# PIC32CM2532LS60048 register map
Vendor: Microchip Technology; Series: PIC32CMLS60; File version: 0
CPU: CM23 r0p0, selectable endian, MPU, no FPU, 2 interrupt priority bits
Registers are 32-bit, read-write, reset 0x0 unless marked. A register's access mark holds for its fields unless they carry their own. Offsets are from the block's base; [hi:lo] are bit positions; {n}, {i} and the like mark numbered series; 'fields as' and 'values as' point back to an identical list.

## MPU — Memory Protection Unit
Base 0xE000ED90; register names take the prefix MPU_
Same registers: MPU_NS 0xE002ED90
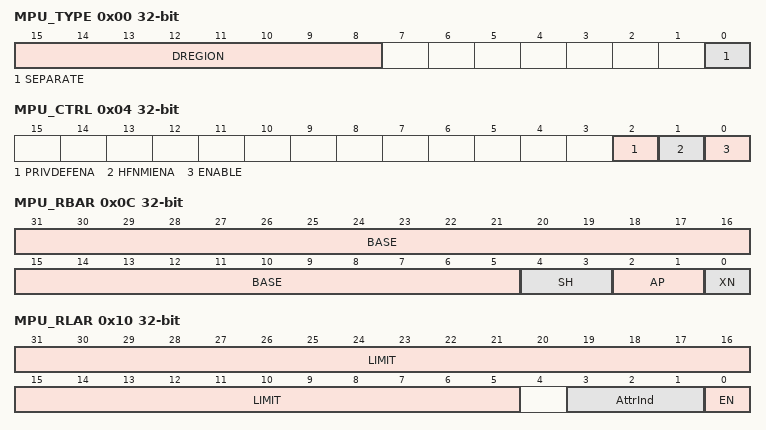
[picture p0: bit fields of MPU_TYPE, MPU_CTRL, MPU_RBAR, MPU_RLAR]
0x00 MPU_TYPE ro
  [15:8] DREGION — Number of MPU data regions
  [0] SEPARATE — Separate instructions and data address regions
0x04 MPU_CTRL — MPU Control Register
  [2] PRIVDEFENA — Privileged default enable
  [1] HFNMIENA — HardFault, NMI enable
  [0] ENABLE — MPU enable
0x08 MPU_RNR — MPU Region Number Register
  [7:0] REGION — Selected region number
0x0C MPU_RBAR — MPU Region Base Address Register
  [31:5] BASE — Base address
  [4:3] SH — Shareability
    0=NO (Non-shareable); 2=OUTER (Outer shareable); 3=INNER (Inner shareable)
  [2:1] AP — Access permissions
    0=RWPRIV (Read/write by privileged code only); 1=RWANY (Read/write by any privilege level); 2=RPRIV (Read-only by privileged code only); 3=RANY (Read-only by any privilege level)
  [0] XN — Execute Never
0x10 MPU_RLAR — MPU Region Limit Address Register
  [31:5] LIMIT — Limit address
  [3:1] AttrInd — Attribute Index
  [0] EN — Region enable
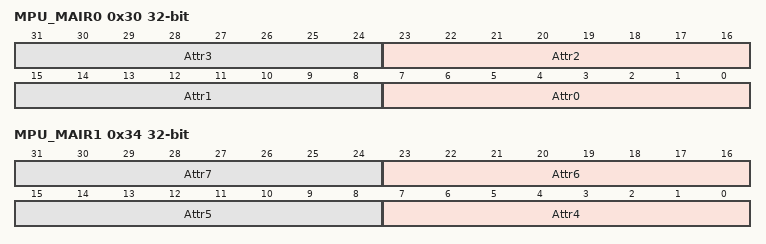
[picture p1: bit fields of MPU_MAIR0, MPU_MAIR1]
0x30 MPU_MAIR0 — MPU Memory Attribute Indirection Register 0
  [8n+7:8n] Attr{n} (n=0..3) — Attribute of MPU region {n}
0x34 MPU_MAIR1 — MPU Memory Attribute Indirection Register 1
  [8n-25:8n-32] Attr{n} (n=4..7) — Attribute of MPU region {n}

## NVIC — Nested Vectored Interrupt Controller
Base 0xE000E100; register names take the prefix NVIC_
Same registers: NVIC_NS 0xE002E100
{0x0+4i} NVIC_ISER[{i}] (i=0..2) — Interrupt Set Enable Register n
  [31:0] SETENA — Set enable
{0x80+4i} NVIC_ICER[{i}] (i=0..2) — Interrupt Clear Enable Register n
  [31:0] CLRENA — Clear enable
{0x100+4i} NVIC_ISPR[{i}] (i=0..2) — Interrupt Set Pending Register n
  [31:0] SETPEND — Set pending
{0x180+4i} NVIC_ICPR[{i}] (i=0..2) — Interrupt Clear Pending Register n
  [31:0] CLRPEND — Clear pending
{0x200+4i} NVIC_IABR[{i}] (i=0..2) ro — Interrupt Active Bit Register n
  [31:0] ACTIVE — Active state
{0x280+4i} NVIC_ITNS[{i}] (i=0..2) — Interrupt Target Non-secure Register n
  [31:0] ITNS — Interrupt Targets Non-secure
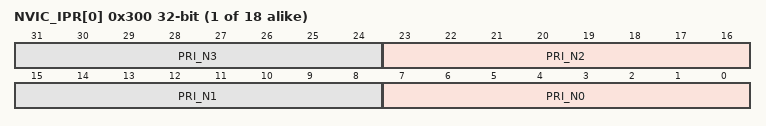
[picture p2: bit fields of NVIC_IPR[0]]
{0x300+4i} NVIC_IPR[{i}] (i=0..17) — Interrupt Priority Register n
  [8n+7:8n] PRI_N{n} (n=0..3) — Priority of interrupt number 4n+{n}

## OSC32KCTRL — 32k Oscillators Control
Base 0x40001400; register names take the prefix OSC32KCTRL_
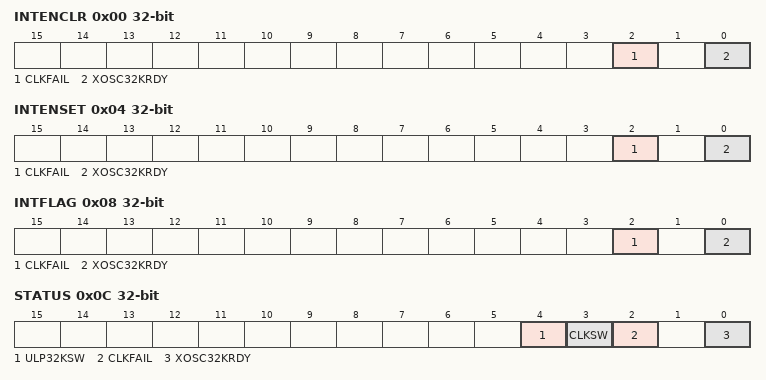
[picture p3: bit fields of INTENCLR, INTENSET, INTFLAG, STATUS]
0x00 INTENCLR — Interrupt Enable Clear
  [2] CLKFAIL — XOSC32K Clock Failure Detector Interrupt Enable
  [0] XOSC32KRDY — XOSC32K Ready Interrupt Enable
0x04 INTENSET — Interrupt Enable Set
  fields as INTENCLR
0x08 INTFLAG — Interrupt Flag Status and Clear
  [2] CLKFAIL — XOSC32K Clock Failure Detector
  [0] XOSC32KRDY — XOSC32K Ready
0x0C STATUS ro — Power and Clocks Status
  [4] ULP32KSW — OSCULP32K Clock Switch
  [3] CLKSW — XOSC32K Clock switch
  [2] CLKFAIL — XOSC32K Clock Failure Detector
  [0] XOSC32KRDY — XOSC32K Ready
0x10 RTCCTRL 8-bit — RTC Clock Selection
  [2:0] RTCSEL
    0=ULP1K (1.024kHz from 32kHz internal ULP oscillator); 1=ULP32K (32.768kHz from 32kHz internal ULP oscillator); 4=XOSC1K (1.024kHz from 32.768kHz external crystal oscillator); 5=XOSC32K (32.768kHz from 32.768kHz external crystal oscillator)
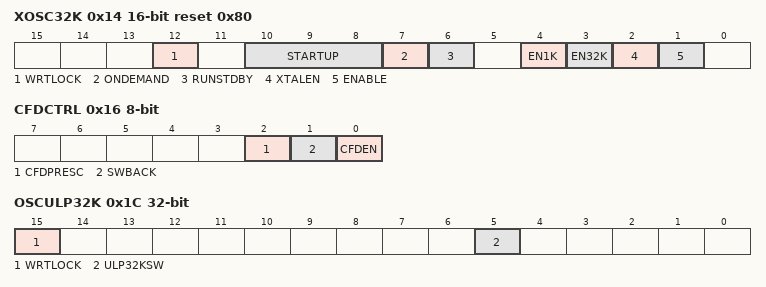
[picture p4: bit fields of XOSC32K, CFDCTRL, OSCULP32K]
0x14 XOSC32K 16-bit reset 0x80 — 32kHz External Crystal Oscillator (XOSC32K) Control
  [12] WRTLOCK — Write Lock
  [10:8] STARTUP — Oscillator Start-Up Time
    0=CYCLE2048 (62.5 ms); 1=CYCLE4096 (125 ms); 2=CYCLE16384 (500 ms); 3=CYCLE32768 (1000 ms); 4=CYCLE65536 (2000 ms); 5=CYCLE131072 (4000 ms); 6=CYCLE262144 (8000 ms)
  [7] ONDEMAND — On Demand Control
  [6] RUNSTDBY — Run in Standby
  [4] EN1K — 1kHz Output Enable
  [3] EN32K — 32kHz Output Enable
  [2] XTALEN — Crystal Oscillator Enable
  [1] ENABLE — Oscillator Enable
0x16 CFDCTRL 8-bit — Clock Failure Detector Control
  [2] CFDPRESC — Clock Failure Detector Prescaler
  [1] SWBACK — Clock Switch Back Enable
  [0] CFDEN — Clock Failure Detector Enable
0x17 EVCTRL 8-bit — Event Control
  [0] CFDEO — Clock Failure Detector Event Output Enable
0x1C OSCULP32K — 32kHz Ultra Low Power Internal Oscillator (OSCULP32K) Control
  [15] WRTLOCK — Write Lock
  [5] ULP32KSW — OSCULP32K Clock Switch Enable

## Notices in the file
Copyright (c) 2017 Microchip Technology Inc.
SPDX-License-Identifier: Apache-2.0
Licensed under the Apache License, Version 2.0 (the "License");
you may not use this file except in compliance with the License.
You may obtain a copy of the License at
http://www.apache.org/licenses/LICENSE-2.0
Unless required by applicable law or agreed to in writing, software
distributed under the License is distributed on an "AS IS" BASIS,
WITHOUT WARRANTIES OR CONDITIONS OF ANY KIND, either express or implied.
See the License for the specific language governing permissions and
limitations under the License.
